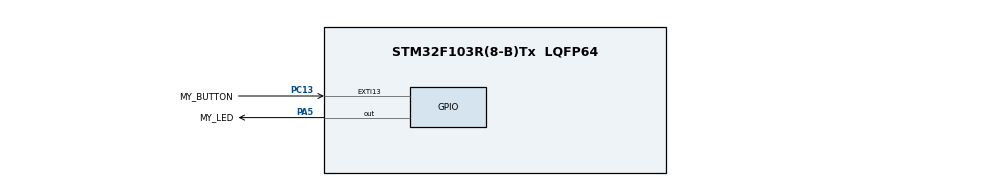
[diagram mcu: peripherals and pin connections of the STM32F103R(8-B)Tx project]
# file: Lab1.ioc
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Mcu.Family=STM32F1
Mcu.Name=STM32F103R(8-B)Tx
Mcu.Package=LQFP64
NVIC.EXTI15_10_IRQn=true\:0\:0\:false\:false\:true\:true\:true\:true
NVIC.PriorityGroup=NVIC_PRIORITYGROUP_4
PA5.GPIO_Label=MY_LED
PA5.Signal=GPIO_Output
PC13-TAMPER-RTC.GPIO_Label=MY_BUTTON
PC13-TAMPER-RTC.GPIO_ModeDefaultEXTI=GPIO_MODE_IT_FALLING
PC13-TAMPER-RTC.GPIO_PuPd=GPIO_PULLUP
PC13-TAMPER-RTC.Signal=GPXTI13
ProjectManager.HeapSize=0x200
ProjectManager.StackSize=0x400
ProjectManager.TargetToolchain=MDK-ARM V5.32
RCC.APB1Freq_Value=8000000
RCC.APB2Freq_Value=8000000
VP_SYS_VS_ND.Mode=No_Debug
board=custom

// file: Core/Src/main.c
/* USER CODE BEGIN Header */
/**
  ******************************************************************************
  * @file           : main.c
  * @brief          : Main program body
  ******************************************************************************
  * @attention
  *
  * Copyright (c) 2025 STMicroelectronics.
  * All rights reserved.
  *
  * This software is licensed under terms that can be found in the LICENSE file
  * in the root directory of this software component.
  * If no LICENSE file comes with this software, it is provided AS-IS.
  *
  ******************************************************************************
  */
/* USER CODE END Header */
#include "main.h"

/* USER CODE BEGIN PD */
#define DOUBLE_CLICK_MS 400
#define BLINK_DELAY_MS 200
#define BLINK_COUNT 3
/* USER CODE END PD */

/* USER CODE BEGIN PV */
volatile uint32_t last_press_time = 0;
volatile uint8_t click_count = 0;
volatile uint8_t blinking = 0;

/* USER CODE END PV */

void SystemClock_Config(void);
static void MX_GPIO_Init(void);

int main(void)
{

  /* MCU Configuration--------------------------------------------------------*/

  /* Reset of all peripherals, Initializes the Flash interface and the Systick. */
  HAL_Init();

  /* Configure the system clock */
  SystemClock_Config();

  /* Initialize all configured peripherals */
  MX_GPIO_Init();
  /* USER CODE BEGIN 2 */
  HAL_GPIO_WritePin(MY_LED_GPIO_Port, MY_LED_Pin, GPIO_PIN_SET);
  /* USER CODE END 2 */

  /* Infinite loop */
  while (1)
  {

    /* USER CODE BEGIN 3 */
    if (!blinking && click_count == 2)
    {
      blinking = 1;
      click_count = 0;

      for (int i = 0; i < BLINK_COUNT; i++)
      {
        HAL_GPIO_TogglePin(MY_LED_GPIO_Port, MY_LED_Pin);
        HAL_Delay(BLINK_DELAY_MS);
        HAL_GPIO_TogglePin(MY_LED_GPIO_Port, MY_LED_Pin);
        HAL_Delay(BLINK_DELAY_MS);
      }

      HAL_GPIO_WritePin(MY_LED_GPIO_Port, MY_LED_Pin, GPIO_PIN_RESET);
      blinking = 0;
    }
  }
  /* USER CODE END 3 */
}

void SystemClock_Config(void)
{
  RCC_OscInitTypeDef RCC_OscInitStruct = {0};
  RCC_ClkInitTypeDef RCC_ClkInitStruct = {0};

  /** Initializes the RCC Oscillators according to the specified parameters
  * in the RCC_OscInitTypeDef structure.
  */
  RCC_OscInitStruct.OscillatorType = RCC_OSCILLATORTYPE_HSI;
  RCC_OscInitStruct.HSIState = RCC_HSI_ON;
  RCC_OscInitStruct.HSICalibrationValue = RCC_HSICALIBRATION_DEFAULT;
  RCC_OscInitStruct.PLL.PLLState = RCC_PLL_NONE;
  if (HAL_RCC_OscConfig(&RCC_OscInitStruct) != HAL_OK)
  {
    Error_Handler();
  }

  /** Initializes the CPU, AHB and APB buses clocks
  */
  RCC_ClkInitStruct.ClockType = RCC_CLOCKTYPE_HCLK|RCC_CLOCKTYPE_SYSCLK
                              |RCC_CLOCKTYPE_PCLK1|RCC_CLOCKTYPE_PCLK2;
  RCC_ClkInitStruct.SYSCLKSource = RCC_SYSCLKSOURCE_HSI;
  RCC_ClkInitStruct.AHBCLKDivider = RCC_SYSCLK_DIV1;
  RCC_ClkInitStruct.APB1CLKDivider = RCC_HCLK_DIV1;
  RCC_ClkInitStruct.APB2CLKDivider = RCC_HCLK_DIV1;

  if (HAL_RCC_ClockConfig(&RCC_ClkInitStruct, FLASH_LATENCY_0) != HAL_OK)
  {
    Error_Handler();
  }
}

static void MX_GPIO_Init(void)
{
  GPIO_InitTypeDef GPIO_InitStruct = {0};

  /* GPIO Ports Clock Enable */
  __HAL_RCC_GPIOC_CLK_ENABLE();
  __HAL_RCC_GPIOA_CLK_ENABLE();

  /*Configure GPIO pin Output Level */
  HAL_GPIO_WritePin(MY_LED_GPIO_Port, MY_LED_Pin, GPIO_PIN_RESET);

  /*Configure GPIO pin : MY_BUTTON_Pin */
  GPIO_InitStruct.Pin = MY_BUTTON_Pin;
  GPIO_InitStruct.Mode = GPIO_MODE_IT_FALLING;
  GPIO_InitStruct.Pull = GPIO_PULLUP;
  HAL_GPIO_Init(MY_BUTTON_GPIO_Port, &GPIO_InitStruct);

  /*Configure GPIO pin : MY_LED_Pin */
  GPIO_InitStruct.Pin = MY_LED_Pin;
  GPIO_InitStruct.Mode = GPIO_MODE_OUTPUT_PP;
  GPIO_InitStruct.Pull = GPIO_NOPULL;
  GPIO_InitStruct.Speed = GPIO_SPEED_FREQ_LOW;
  HAL_GPIO_Init(MY_LED_GPIO_Port, &GPIO_InitStruct);

  /* EXTI interrupt init*/
  HAL_NVIC_SetPriority(EXTI15_10_IRQn, 0, 0);
  HAL_NVIC_EnableIRQ(EXTI15_10_IRQn);

}

/* USER CODE BEGIN 4 */
void HAL_GPIO_EXTI_Callback(uint16_t GPIO_Pin)
{
  if (GPIO_Pin == MY_BUTTON_Pin && !blinking)
  {
    uint32_t now = HAL_GetTick();

    if (now - last_press_time <= DOUBLE_CLICK_MS)
    {
      click_count++;
    }
    else
    {
      click_count = 1;
    }

    last_press_time = now;
  }
}
/* USER CODE END 4 */

void Error_Handler(void)
{
  __disable_irq();
  while (1)
  {
  }
}
